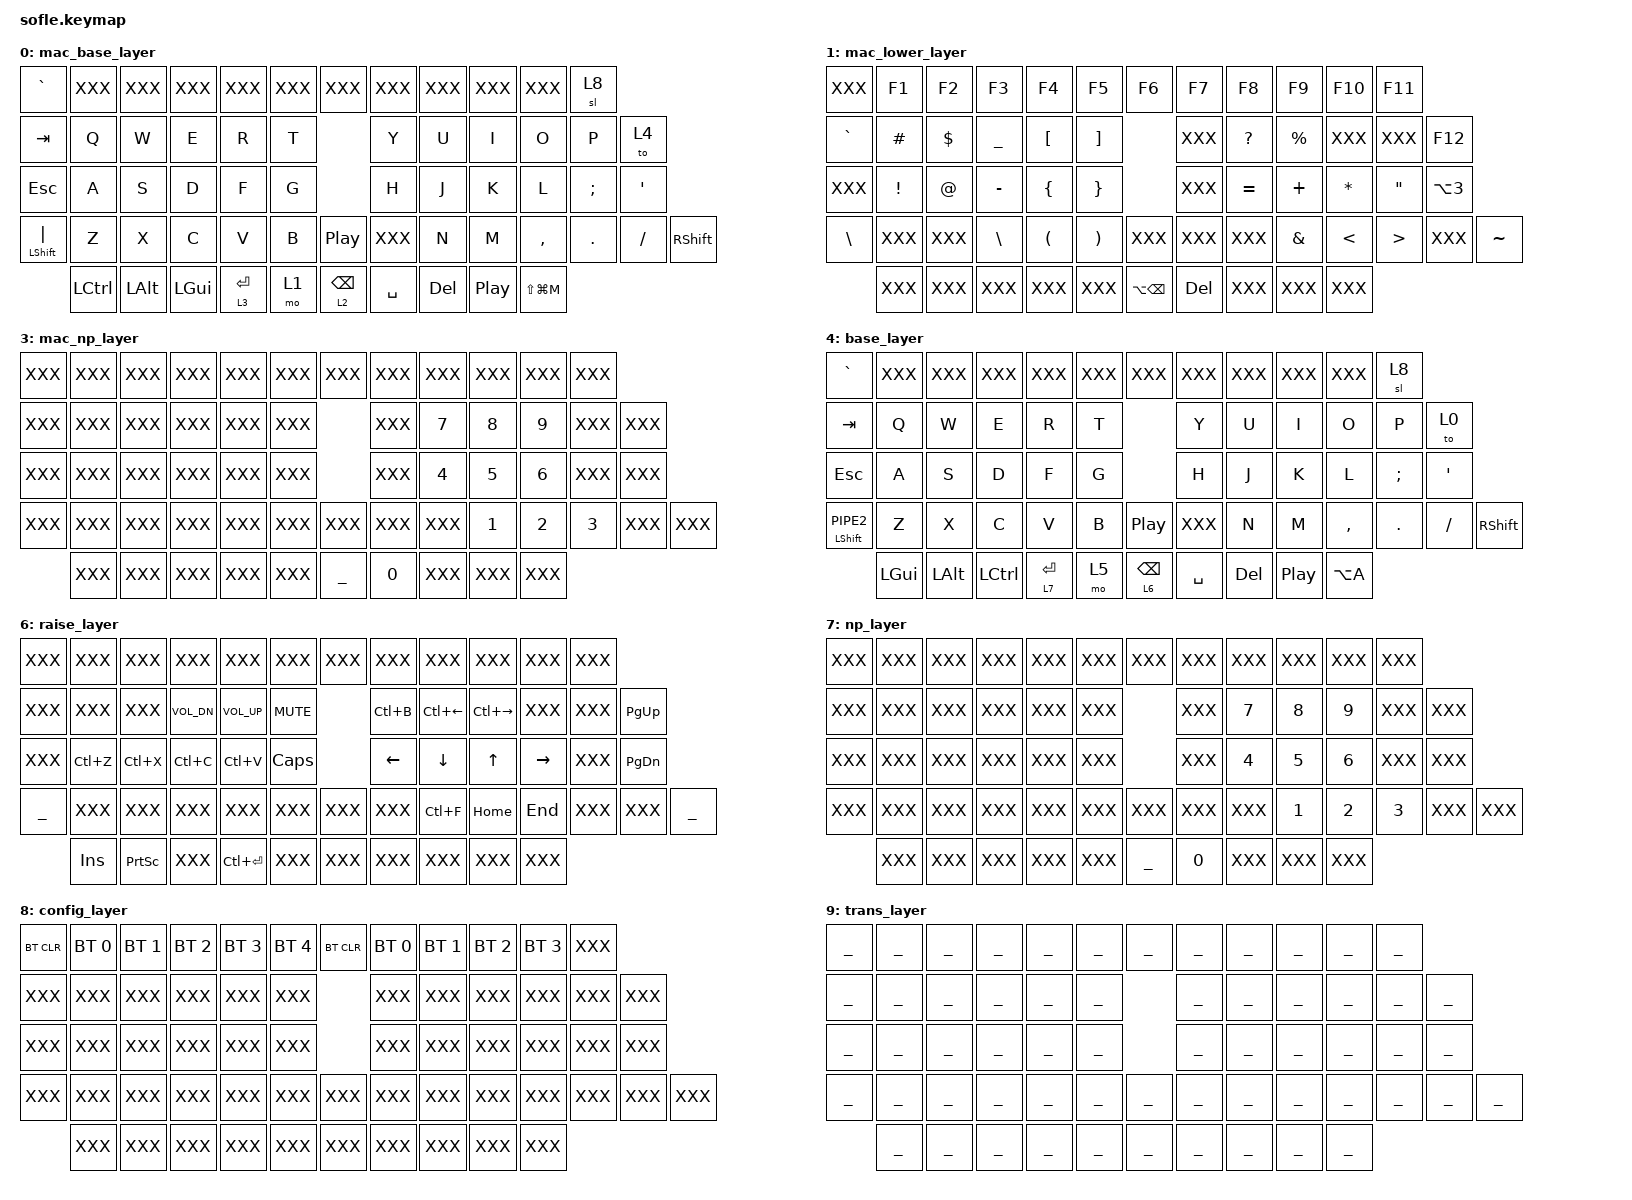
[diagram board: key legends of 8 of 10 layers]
/*
 * Copyright (c) 2020 The ZMK Contributors
 *
 * SPDX-License-Identifier: MIT
 */

#include <behaviors.dtsi>
#include <dt-bindings/zmk/keys.h>
#include <dt-bindings/zmk/bt.h>
#include "sofle.h"


/ { 
    behaviors {
		tp: behavior_tap_preferred {
			compatible = "zmk,behavior-hold-tap";
			label = "MOD_TAP";
			#binding-cells = <2>;
			flavor = "tap-preferred";
			tapping-term-ms = <150>;
			bindings = <&kp>, <&kp>;
		};
	};

    keymap {
        compatible = "zmk,keymap";

// ~~~~~~~~~~~~~~~~~~~~~~~~~~~~~~~~~~~~~~~~~~~~~~~~~~~~~~~~~~~~~~~~~~~~~~~~~~~~~~~~~~~~~~~~~~~~~~~~~~~~~~~~~~~~~~~~~~~~~
        mac_base_layer {
// ---------------------------------------------------------------------------------------------------------------------
// 	|  `~   |       |       |       |       |       |       /*    */       |       |       |       |       |       |  cfg  |
// 	|  TAB  |   Q   |   W   |   E   |   R   |   T   |       /*    */       |   Y   |   U   |   I   |   O   |   P   |  mac  |
// 	|  ESC  |   A   |   S   |   D   |   F   |   G   |       /*    */       |   H   |   J   |   K   |   L   |   :   |   '   |
// 	| SFT/| |   Z   |   X   |   C   |   V   |   B   |       /*    */       |   N   |   M   |   ,   |   .   |   /   | SFT   |
// 	                |  GUI  |  ALT  |  CTRL | ENT/np|  lwr  /*    */ rs/BSP|  SPC  |  DEL  | PLAY  | Tmute |      
            bindings = <
	&kp GRAVE		XXX	XXX		XXX		XXX		XXX			/**/			XXX		XXX		XXX		XXX		XXX		&sl 8
	&kp TAB			&kp Q	&kp W		&kp E		&kp R		&kp T			/**/			&kp Y		&kp U		&kp I		&kp O		&kp P		&to 4 
	&kp ESC			&kp A	&kp S		&kp D		&kp F		&kp G			/**/			&kp H		&kp J		&kp K		&kp L		&kp SEMI	&kp SQT
	&mt LSHFT PIPE	 	&kp Z	&kp X		&kp C		&kp V		&kp B		&kp C_PP/**/	XXX 		&kp N		&kp M		&kp COMMA	&kp DOT		&kp FSLH	&kp RSHIFT
					&kp LCTRL	&kp LALT	&kp LGUI	&lt 3 RET	&mo 1	/**/	&lt 2 BSPC	&kp SPACE	&kp DEL		&kp C_PP	&kp LS(LG(M))
            >;
            sensor-bindings = <&inc_dec_kp C_NEXT C_PREV &inc_dec_kp C_VOL_UP C_VOL_DN>;
        };

// ~~~~~~~~~~~~~~~~~~~~~~~~~~~~~~~~~~~~~~~~~~~~~~~~~~~~~~~~~~~~~~~~~~~~~~~~~~~~~~~~~~~~~~~~~~~~~~~~~~~~~~~~~~~~~~~~~~~~~
        mac_lower_layer {
// ---------------------------------------------------------------------------------------------------------------------
// 	|       |  F1   |  F2   |  F3   |  F4   |  F5   |       /*    */        |  F6   |  F7   |  F8   |  F9   |  F10  |  F11  |
// 	|   `   |   £   |   $   |   _   |   [   |   ]   |       /*    */        |       |   ?   |   %   |       |       |  F12  |
// 	|       |   !   |   "   |   -   |   {   |   }   |       /*    */        |       |   =   |   +   |   *   |   @   |   #   |
// 	|   \   |       |       |   \   |   (   |   )   |       /*    */        |       |   &   |   <   |   >   |       |   ~   |
// 	                |       |       |       |       |       /*    */        | BspWd |       |       |       |      
            bindings = <
	XXX		&kp F1		&kp F2		&kp F3		&kp F4		&kp F5			/**/			&kp F6	&kp F7		&kp F8		&kp F9		&kp F10	&kp F11
	&kp GRAVE	&kp HASH	&kp DLLR	&kp UNDER	&kp LBKT	&kp RBKT		/**/			XXX	&kp QMARK	&kp PRCNT	XXX		XXX	&kp F12
	XXX		&kp EXCL	&kp AT		&kp MINUS	&kp LBRC	&kp RBRC		/**/			XXX	&kp EQUAL	&kp PLUS	&kp STAR	&kp DQT	&kp LA(N3)
	&kp BSLH	XXX		XXX		&kp BSLH	&kp LPAR	&kp RPAR	XXX	/**/	XXX		XXX	&kp AMPS	&kp LT		&kp GT		XXX	&kp TILDE
					XXX		XXX		XXX		XXX		XXX	/**/	&kp LA(BSPC)	&kp DEL	XXX		XXX		XXX
            >;
            sensor-bindings = <&inc_dec_kp C_NEXT C_PREV &inc_dec_kp C_VOL_UP C_VOL_DN>;
        };

// ~~~~~~~~~~~~~~~~~~~~~~~~~~~~~~~~~~~~~~~~~~~~~~~~~~~~~~~~~~~~~~~~~~~~~~~~~~~~~~~~~~~~~~~~~~~~~~~~~~~~~~~~~~~~~~~~~~~~~
        mac_raise_layer {
// ---------------------------------------------------------------------------------------------------------------------
// 	|       |       |       |       |       |       |       /*    */        |       |       |       |       |       |       |
// 	|       |       |       | VOLDN | VOLUP | MUTE  |       /*    */        |  C+b  | PWord | Nword |       |       | PG UP |
// 	|       | UNDO  |  CUT  | COPY  | PASTE | CAPS  |       /*    */        |   <   |   v   |   ^   |   >   |       | PG DN |
// 	|       |       |       | PREV  | NEXT  |       |       /*    */        |  C+f  | HOME  |  END  |       |       |       |
// 	                | INS   | PRT   |       | CMDENT|       /*    */        |       |       |       |       |      
            bindings = <
	XXX	XXX		XXX		XXX		XXX		XXX			/**/		XXX		XXX		XXX		XXX		XXX	XXX
	XXX	XXX		XXX		&kp C_VOL_DN	&kp C_VOL_UP	&kp K_MUTE		/**/		&kp LC(B)	&kp LA(LEFT)	&kp LA(RIGHT)	XXX		XXX	&kp PG_UP
	XXX	&kp LG(Z)	&kp LG(X)	&kp LG(C)	&kp LG(V)	&kp CLCK		/**/		&kp LEFT	&kp DOWN	&kp UP		&kp RIGHT	XXX	&kp PG_DN
	___		XXX		&kp C_PREV	&kp C_NEXT	XXX		XXX	/**/	XXX	&kp LC(F)	&kp HOME	&kp END		XXX		XXX	___
				&kp INS		MAC_PSCR	XXX		&kp LG(RET)	XXX	/**/	XXX	XXX		XXX		XXX		XXX
            >;
            sensor-bindings = <&inc_dec_kp C_VOL_UP C_VOL_DN>;
        };

// ~~~~~~~~~~~~~~~~~~~~~~~~~~~~~~~~~~~~~~~~~~~~~~~~~~~~~~~~~~~~~~~~~~~~~~~~~~~~~~~~~~~~~~~~~~~~~~~~~~~~~~~~~~~~~~~~~~~~~
        mac_np_layer {
// ---------------------------------------------------------------------------------------------------------------------
// 	|       |       |       |       |       |       |       /*    */        |       |       |       |       |       |       |
// 	|       |       |       |       |       |       |       /*    */        |       |   7   |   8   |   9   |       |       |
// 	|       |       |       |       |       |       |       /*    */        |       |   4   |   5   |   6   |       |       |
// 	|       |       |       |       |       |       |       /*    */        |       |   1   |   2   |   3   |       |       |
// 	                |       |       |       |       |       /*    */        |   0   |       |       |       |      
            bindings = <
	XXX	XXX	XXX	XXX	XXX	XXX		/**/		XXX	XXX	XXX	XXX	XXX	XXX
	XXX	XXX	XXX	XXX	XXX	XXX		/**/		XXX	&kp N7	&kp N8	&kp N9	XXX	XXX
	XXX	XXX	XXX	XXX	XXX	XXX		/**/		XXX	&kp N4	&kp N5	&kp N6	XXX	XXX
	XXX	XXX	XXX	XXX	XXX	XXX	XXX	/**/	XXX	XXX	&kp N1	&kp N2	&kp N3	XXX	XXX
			XXX	XXX	XXX	XXX	XXX	/**/	___	&kp N0	XXX	XXX	XXX
            >;
            sensor-bindings = <&inc_dec_kp C_NEXT C_PREV &inc_dec_kp C_VOL_UP C_VOL_DN>;
        };

// ~~~~~~~~~~~~~~~~~~~~~~~~~~~~~~~~~~~~~~~~~~~~~~~~~~~~~~~~~~~~~~~~~~~~~~~~~~~~~~~~~~~~~~~~~~~~~~~~~~~~~~~~~~~~~~~~~~~~~
        base_layer {
// ---------------------------------------------------------------------------------------------------------------------
// 	|  `~   |       |       |       |       |       |       /*    */       |       |       |       |       |       |  cfg  |
// 	|  TAB  |   Q   |   W   |   E   |   R   |   T   |       /*    */       |   Y   |   U   |   I   |   O   |   P   |  mac  |
// 	|  ESC  |   A   |   S   |   D   |   F   |   G   |       /*    */       |   H   |   J   |   K   |   L   |   :   |   '   |
// 	| SFT/| |   Z   |   X   |   C   |   V   |   B   |       /*    */       |   N   |   M   |   ,   |   .   |   /   | SFT   |
// 	                |  GUI  |  ALT  |  CTRL | ENT/np|  lwr  /*    */ rs/BSP|  SPC  |  DEL  | PLAY  | Zmute |      
            bindings = <
	&kp GRAVE		XXX	XXX		XXX		XXX		XXX			/**/			XXX		XXX		XXX		XXX		XXX		&sl 8
	&kp TAB			&kp Q	&kp W		&kp E		&kp R		&kp T			/**/			&kp Y		&kp U		&kp I		&kp O		&kp P		&to 0 
	&kp ESC			&kp A	&kp S		&kp D		&kp F		&kp G			/**/			&kp H		&kp J		&kp K		&kp L		&kp SEMI	&kp SQT
	&mt LSHFT PIPE2 	&kp Z	&kp X		&kp C		&kp V		&kp B		&kp C_PP/**/	XXX 		&kp N		&kp M		&kp COMMA	&kp DOT		&kp FSLH	&kp RSHIFT
					&kp LGUI	&kp LALT	&kp LCTRL	&lt 7 RET	&mo 5	/**/	&lt 6 BSPC	&kp SPACE	&kp DEL		&kp C_PP	&kp LA(A)
            >;
            sensor-bindings = <&inc_dec_kp C_NEXT C_PREV &inc_dec_kp C_VOL_UP C_VOL_DN>;
        };

// ~~~~~~~~~~~~~~~~~~~~~~~~~~~~~~~~~~~~~~~~~~~~~~~~~~~~~~~~~~~~~~~~~~~~~~~~~~~~~~~~~~~~~~~~~~~~~~~~~~~~~~~~~~~~~~~~~~~~~
        lower_layer {
// ---------------------------------------------------------------------------------------------------------------------
// 	|       |  F1   |  F2   |  F3   |  F4   |  F5   |       /*    */        |  F6   |  F7   |  F8   |  F9   |  F10  |  F11  |
// 	|   `   |   £   |   $   |   _   |   [   |   ]   |       /*    */        |       |   ?   |   %   |       |       |  F12  |
// 	|       |   !   |   "   |   -   |   {   |   }   |       /*    */        |       |   =   |   +   |   *   |   @   |   #   |
// 	|       |       |       |   \   |   (   |   )   |       /*    */        |       |   &   |   <   |   >   |       |   ~   |
// 	                |       |       |       |       |       /*    */        | BspWd |       |       |       |      
            bindings = <
	XXX		&kp F1		&kp F2		&kp F3		&kp F4		&kp F5			/**/			&kp F6	&kp F7		&kp F8		&kp F9		&kp F10	&kp F11
	&kp GRAVE	&kp HASH	&kp DLLR	&kp UNDER	&kp LBKT	&kp RBKT		/**/			XXX	&kp QMARK	&kp PRCNT	XXX		XXX	&kp F12
	XXX		&kp EXCL	&kp AT		&kp MINUS	&kp LBRC	&kp RBRC		/**/			XXX	&kp EQUAL	&kp PLUS	&kp STAR	&kp DQT	&kp NON_US_HASH
	XXX		XXX		XXX		&kp NON_US_BSLH	&kp LPAR	&kp RPAR		/**/	XXX		XXX	&kp AMPS	&kp LT		&kp GT		XXX	&kp TILDE2
					XXX		XXX		XXX		XXX		XXX	/**/	&kp LC(BSPC)	XXX	XXX		XXX		XXX
            >;
            sensor-bindings = <&inc_dec_kp C_NEXT C_PREV &inc_dec_kp C_VOL_UP C_VOL_DN>;
        };

// ~~~~~~~~~~~~~~~~~~~~~~~~~~~~~~~~~~~~~~~~~~~~~~~~~~~~~~~~~~~~~~~~~~~~~~~~~~~~~~~~~~~~~~~~~~~~~~~~~~~~~~~~~~~~~~~~~~~~~
        raise_layer {
// ---------------------------------------------------------------------------------------------------------------------
// 	|       |       |       |       |       |       |       /*    */        |       |       |       |       |       |       |
// 	|       |       |       | VOLDN | VOLUP | MUTE  |       /*    */        |  C+B  | PWORD | NWORD |       |       | PG UP |
// 	|       | UNDO  |  CUT  | COPY  | PASTE | CAPS  |       /*    */        |   <   |   V   |   ^   |   >   |       | PG DN |
// 	|       |       |       |       |       |       |       /*    */        |  C+F  | HOME  |  END  |       |       |       |
// 	                | INS   | PRT   |       | CMDENT|       /*    */        |       |       |       |       |      
            bindings = <
	XXX	XXX		XXX		XXX		XXX		XXX			/**/		XXX		XXX		XXX		XXX		XXX	XXX
	XXX	XXX		XXX		&kp C_VOL_DN	&kp C_VOL_UP	&kp K_MUTE		/**/		&kp LC(B)	&kp LC(LEFT)	&kp LC(RIGHT)	XXX		XXX	&kp PG_UP
	XXX	&kp LC(Z)	&kp LC(X)	&kp LC(C)	&kp LC(V)	&kp CLCK		/**/		&kp LEFT	&kp DOWN	&kp UP		&kp RIGHT	XXX	&kp PG_DN
	___	XXX		XXX		XXX		XXX		XXX		XXX	/**/	XXX	&kp LC(F)	&kp HOME	&kp END		XXX		XXX	___
				&kp INS		&kp PSCRN	XXX		&kp LC(RET)	XXX	/**/	XXX	XXX		XXX		XXX		XXX
            >;
            sensor-bindings = <&inc_dec_kp C_VOL_UP C_VOL_DN>;
        };

// ~~~~~~~~~~~~~~~~~~~~~~~~~~~~~~~~~~~~~~~~~~~~~~~~~~~~~~~~~~~~~~~~~~~~~~~~~~~~~~~~~~~~~~~~~~~~~~~~~~~~~~~~~~~~~~~~~~~~~
        np_layer {
// ---------------------------------------------------------------------------------------------------------------------
// 	|       |       |       |       |       |       |       /*    */        |       |       |       |       |       |       |
// 	|       |       |       |       |       |       |       /*    */        |       |   7   |   8   |   9   |       |       |
// 	|       |       |       |       |       |       |       /*    */        |       |   4   |   5   |   6   |       |       |
// 	|       |       |       |       |       |       |       /*    */        |       |   1   |   2   |   3   |       |       |
// 	                |       |       |       |       |       /*    */        |   0   |       |       |       |      
            bindings = <
	XXX	XXX	XXX	XXX	XXX	XXX		/**/		XXX	XXX	XXX	XXX	XXX	XXX
	XXX	XXX	XXX	XXX	XXX	XXX		/**/		XXX	&kp N7	&kp N8	&kp N9	XXX	XXX
	XXX	XXX	XXX	XXX	XXX	XXX		/**/		XXX	&kp N4	&kp N5	&kp N6	XXX	XXX
	XXX	XXX	XXX	XXX	XXX	XXX	XXX	/**/	XXX	XXX	&kp N1	&kp N2	&kp N3	XXX	XXX
			XXX	XXX	XXX	XXX	XXX	/**/	___	&kp N0	XXX	XXX	XXX
            >;
            sensor-bindings = <&inc_dec_kp C_NEXT C_PREV &inc_dec_kp C_VOL_UP C_VOL_DN>;
        };

// ~~~~~~~~~~~~~~~~~~~~~~~~~~~~~~~~~~~~~~~~~~~~~~~~~~~~~~~~~~~~~~~~~~~~~~~~~~~~~~~~~~~~~~~~~~~~~~~~~~~~~~~~~~~~~~~~~~~~~
        config_layer {
// ---------------------------------------------------------------------------------------------------------------------
// 	| BTCLR | BT0   |  BT1  |  BT2  |  BT3  |  BT4  |       /*    */        | BTCLR | BT0   |  BT1  |  BT2  |  BT3  |  BT4  |
// 	|       |       |       |       |       |       |       /*    */        |       |       |       |       |       |       |
// 	|       |       |       |       |       |       |       /*    */        |       |       |       |       |       |       |
// 	|       |       |       |       |       |       |       /*    */        |       |       |       |       |       |       |
// 	                |       |       |       |       |       /*    */        |       |       |       |       |      
            bindings = <
	&bt BT_CLR	&bt BT_SEL 0	&bt BT_SEL 1	&bt BT_SEL 2	&bt BT_SEL 3	&bt BT_SEL 4		/**/			&bt BT_CLR	&bt BT_SEL 0	&bt BT_SEL 1	&bt BT_SEL 2	&bt BT_SEL 3	XXX
	XXX		XXX		XXX		XXX		XXX		XXX			/**/			XXX		XXX		XXX		XXX		XXX		XXX
	XXX		XXX		XXX		XXX		XXX		XXX			/**/			XXX		XXX		XXX		XXX		XXX		XXX
	XXX		XXX		XXX		XXX		XXX		XXX		XXX	/**/	XXX		XXX		XXX		XXX		XXX		XXX		XXX
					XXX		XXX		XXX		XXX		XXX	/**/	XXX		XXX		XXX		XXX		XXX
            >;
            sensor-bindings = <&inc_dec_kp C_NEXT C_PREV &inc_dec_kp C_VOL_UP C_VOL_DN>;
        };


// ~~~~~~~~~~~~~~~~~~~~~~~~~~~~~~~~~~~~~~~~~~~~~~~~~~~~~~~~~~~~~~~~~~~~~~~~~~~~~~~~~~~~~~~~~~~~~~~~~~~~~~~~~~~~~~~~~~~~~
        trans_layer {
// ---------------------------------------------------------------------------------------------------------------------
// 	|       |       |       |       |       |       |       /*    */        |       |       |       |       |       |       |
// 	|       |       |       |       |       |       |       /*    */        |       |       |       |       |       |       |
// 	|       |       |       |       |       |       |       /*    */        |       |       |       |       |       |       |
// 	|       |       |       |       |       |       |       /*    */        |       |       |       |       |       |       |
// 	                |       |       |       |       |       /*    */        |       |       |       |       |      
            bindings = <
	___	___	___	___	___	___		/**/		___	___	___	___	___	___
	___	___	___	___	___	___		/**/		___	___	___	___	___	___
	___	___	___	___	___	___		/**/		___	___	___	___	___	___
	___	___	___	___	___	___	___	/**/	___	___	___	___	___	___	___
			___	___	___	___	___	/**/	___	___	___	___	___
            >;
            sensor-bindings = <&inc_dec_kp C_NEXT C_PREV &inc_dec_kp C_VOL_UP C_VOL_DN>;
        };

    };
};
